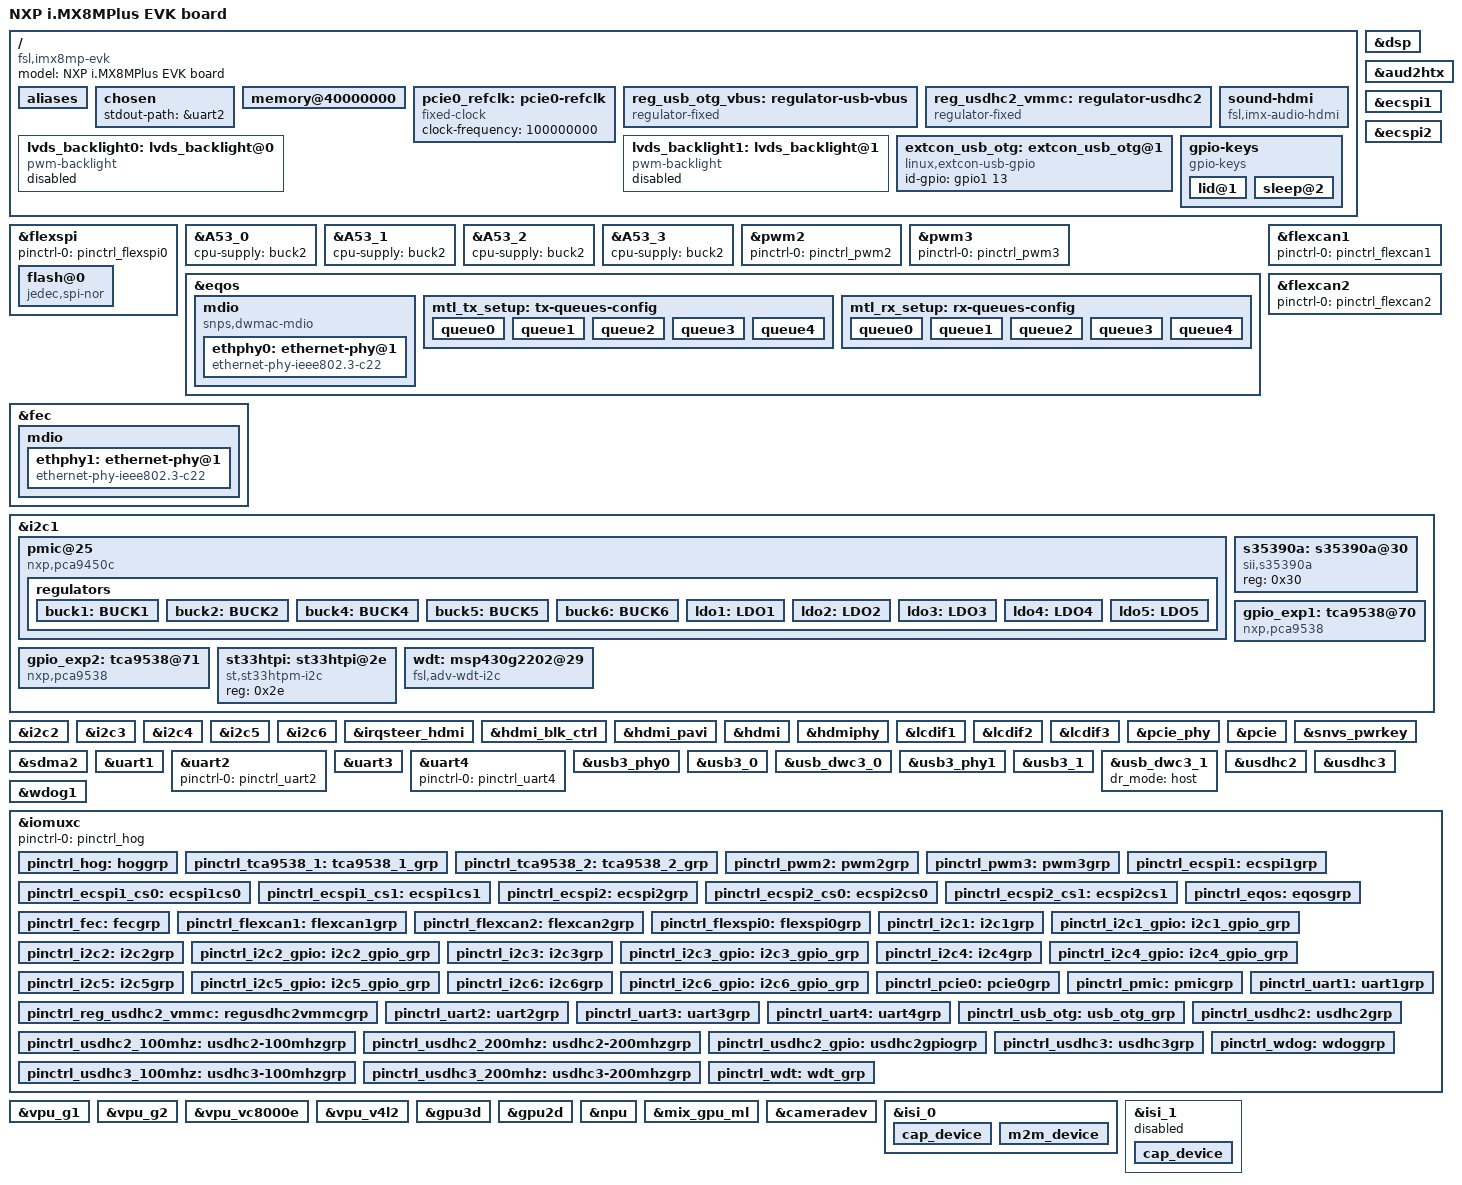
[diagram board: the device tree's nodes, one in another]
// SPDX-License-Identifier: (GPL-2.0+ OR MIT)
/*
 * Copyright 2019 NXP
 */

/dts-v1/;

#include <dt-bindings/phy/phy-imx8-pcie.h>
#include <dt-bindings/usb/pd.h>
#include "imx8mp.dtsi"
#include "imx8mp-nxp-display.dtsi"
#include "imx8mp-nxp-capture.dtsi"

/ {
	model = "NXP i.MX8MPlus EVK board";
	compatible = "fsl,imx8mp-evk", "fsl,imx8mp";

	aliases {
		rtc0 = &s35390a;
		rtc1 = &snvs_rtc;
	};

	aliases {
		watchdog0 = &wdog1;
		watchdog1 = &wdt;
	};

	chosen {
		stdout-path = &uart2;
	};

	memory@40000000 {
		device_type = "memory";
		reg = <0x0 0x40000000 0 0xc0000000>,
		      <0x1 0x00000000 0 0xc0000000>;
	};

	pcie0_refclk: pcie0-refclk {
		compatible = "fixed-clock";
		#clock-cells = <0>;
		clock-frequency = <100000000>;
	};

	reg_usb_otg_vbus: regulator-usb-vbus {
		compatible = "regulator-fixed";
		regulator-name = "usb_otg_vbus";
		regulator-min-microvolt = <5000000>;
		regulator-max-microvolt = <5000000>;
		gpio = <&gpio1 12 GPIO_ACTIVE_HIGH>;
		enable-active-high;
		regulator-always-on;
	};

	reg_usdhc2_vmmc: regulator-usdhc2 {
		compatible = "regulator-fixed";
		pinctrl-names = "default";
		pinctrl-0 = <&pinctrl_reg_usdhc2_vmmc>;
		regulator-name = "VSD_3V3";
		regulator-min-microvolt = <3300000>;
		regulator-max-microvolt = <3300000>;
		gpio = <&gpio2 19 GPIO_ACTIVE_HIGH>;
		enable-active-high;
	};

	sound-hdmi {
		compatible = "fsl,imx-audio-hdmi";
		model = "audio-hdmi";
		audio-cpu = <&aud2htx>;
		hdmi-out;
		constraint-rate = <44100>,
				<88200>,
				<176400>,
				<32000>,
				<48000>,
				<96000>,
				<192000>;
		status = "okay";
	};

	lvds_backlight0: lvds_backlight@0 {
		compatible = "pwm-backlight";
		pwms = <&pwm2 0 5000000 0>;
		status = "disabled";

		brightness-levels = < 0  1  2  3  4  5  6  7  8  9
				     10 11 12 13 14 15 16 17 18 19
				     20 21 22 23 24 25 26 27 28 29
				     30 31 32 33 34 35 36 37 38 39
				     40 41 42 43 44 45 46 47 48 49
				     50 51 52 53 54 55 56 57 58 59
				     60 61 62 63 64 65 66 67 68 69
				     70 71 72 73 74 75 76 77 78 79
				     80 81 82 83 84 85 86 87 88 89
				     90 91 92 93 94 95 96 97 98 99
				    100>;
		default-brightness-level = <80>;
	};

	lvds_backlight1: lvds_backlight@1 {
		compatible = "pwm-backlight";
		pwms = <&pwm3 0 5000000 0>;
		status = "disabled";

		brightness-levels = < 0  1  2  3  4  5  6  7  8  9
				     10 11 12 13 14 15 16 17 18 19
				     20 21 22 23 24 25 26 27 28 29
				     30 31 32 33 34 35 36 37 38 39
				     40 41 42 43 44 45 46 47 48 49
				     50 51 52 53 54 55 56 57 58 59
				     60 61 62 63 64 65 66 67 68 69
				     70 71 72 73 74 75 76 77 78 79
				     80 81 82 83 84 85 86 87 88 89
				     90 91 92 93 94 95 96 97 98 99
				    100>;
		default-brightness-level = <80>;
	};

	extcon_usb_otg: extcon_usb_otg@1 {
		compatible = "linux,extcon-usb-gpio";
		id-gpio = <&gpio1 13 GPIO_ACTIVE_HIGH>;
	};

	gpio-keys {
		compatible = "gpio-keys";
		#address-cells = <1>;
		#size-cells = <0>;
		pinctrl-names = "default";

		lid@1 {
			label = "LID KEY";
			gpios = <&gpio_exp1 6 GPIO_ACTIVE_HIGH>;
			linux,input-type = <EV_PWR>; //EV_KEY 1, EV_PWR 22
			linux,code = <KEY_SUSPEND>; //KEY_SUSPEND 205, KEY_SLEEP 142, KEY_POWER 116
			wakeup-source;
			debounce-interval = <100>;
		};

		sleep@2 {
			label = "SLEEP KEY";
			gpios = <&gpio_exp1 7 GPIO_ACTIVE_HIGH>;
			linux,input-type = <EV_PWR>; //EV_KEY 1, EV_PWR 22
			linux,code = <KEY_SLEEP>; //KEY_SUSPEND 205, KEY_SLEEP 142, KEY_POWER 116
			wakeup-source;
			debounce-interval = <100>;
		};
	};
};

&flexspi {
	pinctrl-names = "default";
	pinctrl-0 = <&pinctrl_flexspi0>;
	status = "okay";

	flash@0 {
		compatible = "jedec,spi-nor";
		reg = <0>;
		spi-max-frequency = <29000000>;
		spi-tx-bus-width = <4>;
		spi-rx-bus-width = <4>;
	};
};

&A53_0 {
	cpu-supply = <&buck2>;
};

&A53_1 {
	cpu-supply = <&buck2>;
};

&A53_2 {
	cpu-supply = <&buck2>;
};

&A53_3 {
	cpu-supply = <&buck2>;
};

&dsp {
	status = "okay";
};

&pwm2 {
	pinctrl-names = "default";
	pinctrl-0 = <&pinctrl_pwm2>;
	status = "okay";
};

&pwm3 {
	pinctrl-names = "default";
	pinctrl-0 = <&pinctrl_pwm3>;
	status = "okay";
};

&aud2htx {
	status = "okay";
};

&ecspi1 {
	#address-cells = <1>;
	#size-cells = <0>;
	fsl,spi-num-chipselects = <2>;
	pinctrl-names = "default";
	pinctrl-0 = <&pinctrl_ecspi1 &pinctrl_ecspi1_cs0 &pinctrl_ecspi1_cs1>;
	cs-gpios = <&gpio5 9 GPIO_ACTIVE_LOW>, <&gpio1 7 GPIO_ACTIVE_LOW>;
	status = "okay";
};

&ecspi2 {
	#address-cells = <1>;
	#size-cells = <0>;
	fsl,spi-num-chipselects = <2>;
	pinctrl-names = "default";
	pinctrl-0 = <&pinctrl_ecspi2 &pinctrl_ecspi2_cs0 &pinctrl_ecspi2_cs1>;
	cs-gpios = <&gpio5 13 GPIO_ACTIVE_LOW>, <&gpio1 8 GPIO_ACTIVE_LOW>;
	status = "okay";
};

&eqos {
	pinctrl-names = "default";
	pinctrl-0 = <&pinctrl_eqos>;
	phy-mode = "rgmii-id";
	phy-handle = <&ethphy0>;
	snps,force_thresh_dma_mode;
	snps,mtl-tx-config = <&mtl_tx_setup>;
	snps,mtl-rx-config = <&mtl_rx_setup>;
	status = "okay";

	mdio {
		compatible = "snps,dwmac-mdio";
		#address-cells = <1>;
		#size-cells = <0>;

		ethphy0: ethernet-phy@1 {
			compatible = "ethernet-phy-ieee802.3-c22";
			reg = <1>;
			eee-broken-1000t;
			reset-gpios = <&gpio4 22 GPIO_ACTIVE_LOW>;
			reset-assert-us = <10000>;
			reset-deassert-us = <80000>;
			realtek,clkout-disable;
		};
	};

	mtl_tx_setup: tx-queues-config {
		snps,tx-queues-to-use = <5>;
		snps,tx-sched-sp;

		queue0 {
			snps,dcb-algorithm;
			snps,priority = <0x1>;
		};

		queue1 {
			snps,dcb-algorithm;
			snps,priority = <0x2>;
		};

		queue2 {
			snps,dcb-algorithm;
			snps,priority = <0x4>;
		};

		queue3 {
			snps,dcb-algorithm;
			snps,priority = <0x8>;
		};

		queue4 {
			snps,dcb-algorithm;
			snps,priority = <0xf0>;
		};
	};

	mtl_rx_setup: rx-queues-config {
		snps,rx-queues-to-use = <5>;
		snps,rx-sched-sp;

		queue0 {
			snps,dcb-algorithm;
			snps,priority = <0x1>;
			snps,map-to-dma-channel = <0>;
		};

		queue1 {
			snps,dcb-algorithm;
			snps,priority = <0x2>;
			snps,map-to-dma-channel = <1>;
		};

		queue2 {
			snps,dcb-algorithm;
			snps,priority = <0x4>;
			snps,map-to-dma-channel = <2>;
		};

		queue3 {
			snps,dcb-algorithm;
			snps,priority = <0x8>;
			snps,map-to-dma-channel = <3>;
		};

		queue4 {
			snps,dcb-algorithm;
			snps,priority = <0xf0>;
			snps,map-to-dma-channel = <4>;
		};
	};
};

&fec {
	pinctrl-names = "default";
	pinctrl-0 = <&pinctrl_fec>;
	phy-mode = "rgmii-id";
	phy-handle = <&ethphy1>;
	fsl,magic-packet;
	status = "okay";

	mdio {
		#address-cells = <1>;
		#size-cells = <0>;

		ethphy1: ethernet-phy@1 {
			compatible = "ethernet-phy-ieee802.3-c22";
			reg = <1>;
			eee-broken-1000t;
			reset-gpios = <&gpio4 2 GPIO_ACTIVE_LOW>;
			reset-assert-us = <10000>;
			reset-deassert-us = <80000>;
			realtek,aldps-enable;
			realtek,clkout-disable;
		};
	};
};

&flexcan1 {
	pinctrl-names = "default";
	pinctrl-0 = <&pinctrl_flexcan1>;
	status = "okay";
};

&flexcan2 {
	pinctrl-names = "default";
	pinctrl-0 = <&pinctrl_flexcan2>;
	status = "okay";
};

&i2c1 {
	clock-frequency = <400000>;
	pinctrl-names = "default", "gpio";
	pinctrl-0 = <&pinctrl_i2c1>;
	pinctrl-1 = <&pinctrl_i2c1_gpio>;
	scl-gpios = <&gpio5 14 GPIO_ACTIVE_HIGH>;
	sda-gpios = <&gpio5 15 GPIO_ACTIVE_HIGH>;
	status = "okay";

	pmic@25 {
		compatible = "nxp,pca9450c";
		reg = <0x25>;
		pinctrl-names = "default";
		pinctrl-0 = <&pinctrl_pmic>;
		interrupt-parent = <&gpio1>;
		interrupts = <3 IRQ_TYPE_LEVEL_LOW>;
		nxp,i2c-lt-enable;

		regulators {
			buck1: BUCK1 {
				regulator-name = "BUCK1";
				regulator-min-microvolt = <600000>;
				regulator-max-microvolt = <2187500>;
				regulator-boot-on;
				regulator-always-on;
				regulator-ramp-delay = <3125>;
			};

			buck2: BUCK2 {
				regulator-name = "BUCK2";
				regulator-min-microvolt = <600000>;
				regulator-max-microvolt = <2187500>;
				regulator-boot-on;
				regulator-always-on;
				regulator-ramp-delay = <3125>;
				nxp,dvs-run-voltage = <950000>;
				nxp,dvs-standby-voltage = <850000>;
			};

			buck4: BUCK4{
				regulator-name = "BUCK4";
				regulator-min-microvolt = <600000>;
				regulator-max-microvolt = <3400000>;
				regulator-boot-on;
				regulator-always-on;
			};

			buck5: BUCK5{
				regulator-name = "BUCK5";
				regulator-min-microvolt = <600000>;
				regulator-max-microvolt = <3400000>;
				regulator-boot-on;
				regulator-always-on;
			};

			buck6: BUCK6 {
				regulator-name = "BUCK6";
				regulator-min-microvolt = <600000>;
				regulator-max-microvolt = <3400000>;
				regulator-boot-on;
				regulator-always-on;
			};

			ldo1: LDO1 {
				regulator-name = "LDO1";
				regulator-min-microvolt = <1600000>;
				regulator-max-microvolt = <3300000>;
				regulator-boot-on;
				regulator-always-on;
			};

			ldo2: LDO2 {
				regulator-name = "LDO2";
				regulator-min-microvolt = <800000>;
				regulator-max-microvolt = <1150000>;
				regulator-boot-on;
				regulator-always-on;
			};

			ldo3: LDO3 {
				regulator-name = "LDO3";
				regulator-min-microvolt = <800000>;
				regulator-max-microvolt = <3300000>;
				regulator-boot-on;
				regulator-always-on;
			};

			ldo4: LDO4 {
				regulator-name = "LDO4";
				regulator-min-microvolt = <800000>;
				regulator-max-microvolt = <3300000>;
				regulator-boot-on;
				regulator-always-on;
			};

			ldo5: LDO5 {
				regulator-name = "LDO5";
				regulator-min-microvolt = <1800000>;
				regulator-max-microvolt = <3300000>;
				regulator-boot-on;
				regulator-always-on;
			};
		};
	};

	s35390a: s35390a@30 {
		compatible = "sii,s35390a";
		reg = <0x30>;
		status = "okay";
	};

	gpio_exp1: tca9538@70 {
		compatible = "nxp,pca9538";
		reg = <0x70>;
		pinctrl-0 = <&pinctrl_tca9538_1>;
		interrupt-parent = <&gpio4>;
		interrupts = <0 IRQ_TYPE_EDGE_FALLING>;
		gpio-controller;
		#gpio-cells = <2>;
		interrupt-controller;
		#interrupt-cells = <2>;
	};

	gpio_exp2: tca9538@71 {
		compatible = "nxp,pca9538";
		reg = <0x71>;
		pinctrl-0 = <&pinctrl_tca9538_2>;
		interrupt-parent = <&gpio4>;
		interrupts = <1 IRQ_TYPE_EDGE_FALLING>;
		gpio-controller;
		#gpio-cells = <2>;
		interrupt-controller;
		#interrupt-cells = <2>;
	};

	st33htpi: st33htpi@2e {
		compatible = "st,st33htpm-i2c";
		reg = <0x2e>;
		pinctrl-names = "default";
	};

	wdt: msp430g2202@29 {
		compatible = "fsl,adv-wdt-i2c";
		reg = <0x29>;
		pinctrl-names = "default";
		pinctrl-0 = <&pinctrl_wdt>;
		wdt-en-gpio = <&gpio3 19 GPIO_ACTIVE_HIGH>;
		wdt-ping-gpio = <&gpio4 20 GPIO_ACTIVE_HIGH>;
		status = "okay";
	};
};

&i2c2 {
	clock-frequency = <400000>;
	pinctrl-names = "default", "gpio";
	pinctrl-0 = <&pinctrl_i2c2>;
	pinctrl-1 = <&pinctrl_i2c2_gpio>;
	scl-gpios = <&gpio5 16 GPIO_ACTIVE_HIGH>;
	sda-gpios = <&gpio5 17 GPIO_ACTIVE_HIGH>;
	status = "okay";
};

&i2c3 {
	clock-frequency = <400000>;
	pinctrl-names = "default", "gpio";
	pinctrl-0 = <&pinctrl_i2c3>;
	pinctrl-1 = <&pinctrl_i2c3_gpio>;
	scl-gpios = <&gpio5 18 GPIO_ACTIVE_HIGH>;
	sda-gpios = <&gpio5 19 GPIO_ACTIVE_HIGH>;
	status = "okay";
};

&i2c4 {
	clock-frequency = <100000>;
	pinctrl-names = "default", "gpio";
	pinctrl-0 = <&pinctrl_i2c4>;
	pinctrl-1 = <&pinctrl_i2c4_gpio>;
	scl-gpios = <&gpio2 4 GPIO_ACTIVE_HIGH>;
	sda-gpios = <&gpio2 5 GPIO_ACTIVE_HIGH>;
	status = "okay";
};

&i2c5 {
	clock-frequency = <100000>;
	pinctrl-names = "default", "gpio";
	pinctrl-0 = <&pinctrl_i2c5>;
	pinctrl-1 = <&pinctrl_i2c5_gpio>;
	scl-gpios = <&gpio2 0 GPIO_ACTIVE_HIGH>;
	sda-gpios = <&gpio2 1 GPIO_ACTIVE_HIGH>;
	status = "okay";
};

&i2c6 {
	clock-frequency = <100000>;
	pinctrl-names = "default", "gpio";
	pinctrl-0 = <&pinctrl_i2c6>;
	pinctrl-1 = <&pinctrl_i2c6_gpio>;
	scl-gpios = <&gpio3 28 GPIO_ACTIVE_HIGH>;
	sda-gpios = <&gpio3 20 GPIO_ACTIVE_HIGH>;
	status = "okay";
};

&irqsteer_hdmi {
	status = "okay";
};

&hdmi_blk_ctrl {
	status = "okay";
};

&hdmi_pavi {
	status = "okay";
};

&hdmi {
	status = "okay";
};

&hdmiphy {
	status = "okay";
};

&lcdif1 {
	status = "okay";
};

&lcdif2 {
	status = "okay";
};

&lcdif3 {
	status = "okay";

	thres-low  = <1 2>;             /* (FIFO * 1 / 2) */
	thres-high = <3 4>;             /* (FIFO * 3 / 4) */
};

&pcie_phy {
	fsl,refclk-pad-mode = <IMX8_PCIE_REFCLK_PAD_INPUT>;
	clocks = <&pcie0_refclk>;
	clock-names = "ref";
	status = "okay";
};

&pcie {
	pinctrl-names = "default";
	pinctrl-0 = <&pinctrl_pcie0>;
	reset-gpio = <&gpio1 9 GPIO_ACTIVE_LOW>;      /* M2_RESET# */
	clocks = <&clk IMX8MP_CLK_HSIO_ROOT>,
		 <&clk IMX8MP_CLK_PCIE_ROOT>,
		 <&clk IMX8MP_CLK_HSIO_AXI>;
	clock-names = "pcie", "pcie_aux", "pcie_bus";
	assigned-clocks = <&clk IMX8MP_CLK_PCIE_AUX>;
	assigned-clock-rates = <10000000>;
	assigned-clock-parents = <&clk IMX8MP_SYS_PLL2_50M>;
	status = "okay";
};

&snvs_pwrkey {
	status = "okay";
};

&sdma2 {
	status = "okay";
};

&uart1 { /* BT */
	pinctrl-names = "default";
	pinctrl-0 = <&pinctrl_uart1>;
	assigned-clocks = <&clk IMX8MP_CLK_UART1>;
	assigned-clock-parents = <&clk IMX8MP_SYS_PLL1_80M>;
	uart-has-rtscts;
	status = "okay";
};

&uart2 {
	/* console */
	pinctrl-names = "default";
	pinctrl-0 = <&pinctrl_uart2>;
	status = "okay";
};

&uart3 {
	pinctrl-names = "default";
	pinctrl-0 = <&pinctrl_uart3>;
	assigned-clocks = <&clk IMX8MP_CLK_UART3>;
	assigned-clock-parents = <&clk IMX8MP_SYS_PLL1_80M>;
	fsl,uart-has-rtscts;
	linux,rs485-enabled-at-boot-time;
	rs485-rx-during-tx;
	rs485-rts-active-low;
	status = "okay";
};

&uart4 {
	pinctrl-names = "default";
	pinctrl-0 = <&pinctrl_uart4>;
	status = "okay";
};

&usb3_phy0 {
	fsl,phy-tx-vref-tune = <0xe>;
	fsl,phy-tx-preemp-amp-tune = <3>;
	fsl,phy-tx-vboost-level = <5>;
	fsl,phy-comp-dis-tune = <7>;
	fsl,pcs-tx-deemph-3p5db = <0x21>;
	fsl,phy-pcs-tx-swing-full = <0x7f>;
	status = "okay";
};

&usb3_0 {
	status = "okay";
};

&usb_dwc3_0 {
	pinctrl-names = "default";
	pinctrl-0 = <&pinctrl_usb_otg>;
	dr_mode = "otg";
	extcon = <&extcon_usb_otg>;
	vbus-supply = <&reg_usb_otg_vbus>;
	status = "okay";
};

&usb3_phy1 {
	fsl,phy-tx-preemp-amp-tune = <3>;
	fsl,phy-tx-vref-tune = <0xb>;
	status = "okay";
};

&usb3_1 {
	status = "okay";
};

&usb_dwc3_1 {
	dr_mode = "host";
	status = "okay";
};

&usdhc2 {
	assigned-clocks = <&clk IMX8MP_CLK_USDHC2>;
	assigned-clock-rates = <400000000>;
	pinctrl-names = "default", "state_100mhz", "state_200mhz";
	pinctrl-0 = <&pinctrl_usdhc2>, <&pinctrl_usdhc2_gpio>;
	pinctrl-1 = <&pinctrl_usdhc2_100mhz>, <&pinctrl_usdhc2_gpio>;
	pinctrl-2 = <&pinctrl_usdhc2_200mhz>, <&pinctrl_usdhc2_gpio>;
	wp-gpios = <&gpio2 20 GPIO_ACTIVE_HIGH>;
	cd-gpios = <&gpio2 12 GPIO_ACTIVE_LOW>;
	vmmc-supply = <&reg_usdhc2_vmmc>;
	bus-width = <4>;
	status = "okay";
};

&usdhc3 {
	assigned-clocks = <&clk IMX8MP_CLK_USDHC3>;
	assigned-clock-rates = <400000000>;
	pinctrl-names = "default", "state_100mhz", "state_200mhz";
	pinctrl-0 = <&pinctrl_usdhc3>;
	pinctrl-1 = <&pinctrl_usdhc3_100mhz>;
	pinctrl-2 = <&pinctrl_usdhc3_200mhz>;
	bus-width = <8>;
	cqe-disabled;
	non-removable;
	status = "okay";
};

&wdog1 {
	pinctrl-names = "default";
	pinctrl-0 = <&pinctrl_wdog>;
	fsl,ext-reset-output;
	status = "okay";
};

&iomuxc {
	pinctrl-names = "default";
	pinctrl-0 = <&pinctrl_hog>;

	pinctrl_hog: hoggrp {
		fsl,pins = <
			MX8MP_IOMUXC_HDMI_DDC_SCL__HDMIMIX_HDMI_SCL	0x400001c2
			MX8MP_IOMUXC_HDMI_DDC_SDA__HDMIMIX_HDMI_SDA	0x400001c2
			MX8MP_IOMUXC_HDMI_HPD__HDMIMIX_HDMI_HPD		0x40000010
			MX8MP_IOMUXC_SAI2_MCLK__GPIO4_IO27		0x10		/* GPIO4 */
			MX8MP_IOMUXC_SPDIF_EXT_CLK__GPIO5_IO05	0x10		/* GPIO5 */
			MX8MP_IOMUXC_UART3_RXD__GPIO5_IO26		0x10		/* GPIO6 */
			MX8MP_IOMUXC_UART3_TXD__GPIO5_IO27		0x10		/* GPIO7 */
		>;
	};

	pinctrl_tca9538_1: tca9538_1_grp {
		fsl,pins = <
			MX8MP_IOMUXC_SAI1_RXFS__GPIO4_IO00	0x1c4	/* I2C_EXP_INT0# */
		>;
	};

	pinctrl_tca9538_2: tca9538_2_grp {
		fsl,pins = <
			MX8MP_IOMUXC_SAI1_RXC__GPIO4_IO01	0x1c4	/* I2C_EXP_INT1# */
		>;
	};

	pinctrl_pwm2: pwm2grp {
		fsl,pins = <
			MX8MP_IOMUXC_SAI5_RXD0__PWM2_OUT	0x116
		>;
	};

	pinctrl_pwm3: pwm3grp {
		fsl,pins = <
			MX8MP_IOMUXC_GPIO1_IO10__PWM3_OUT		0x116
		>;
	};

	pinctrl_ecspi1: ecspi1grp {
		fsl,pins = <
			MX8MP_IOMUXC_ECSPI1_SCLK__ECSPI1_SCLK           0x82
			MX8MP_IOMUXC_ECSPI1_MOSI__ECSPI1_MOSI           0x82
			MX8MP_IOMUXC_ECSPI1_MISO__ECSPI1_MISO           0x82
		>;
	};

	pinctrl_ecspi1_cs0: ecspi1cs0 {
		fsl,pins = <
			MX8MP_IOMUXC_ECSPI1_SS0__GPIO5_IO09             0x10
		>;
	};

	pinctrl_ecspi1_cs1: ecspi1cs1 {
		fsl,pins = <
			MX8MP_IOMUXC_GPIO1_IO07__GPIO1_IO07             0x10
		>;
	};

	pinctrl_ecspi2: ecspi2grp {
		fsl,pins = <
			MX8MP_IOMUXC_ECSPI2_SCLK__ECSPI2_SCLK           0x82
			MX8MP_IOMUXC_ECSPI2_MOSI__ECSPI2_MOSI           0x82
			MX8MP_IOMUXC_ECSPI2_MISO__ECSPI2_MISO           0x82
		>;
	};

	pinctrl_ecspi2_cs0: ecspi2cs0 {
		fsl,pins = <
			MX8MP_IOMUXC_ECSPI2_SS0__GPIO5_IO13             0x10
		>;
	};

	pinctrl_ecspi2_cs1: ecspi2cs1 {
		fsl,pins = <
			MX8MP_IOMUXC_GPIO1_IO08__GPIO1_IO08             0x10
		>;
	};

	pinctrl_eqos: eqosgrp {
		fsl,pins = <
			MX8MP_IOMUXC_ENET_MDC__ENET_QOS_MDC				0x2
			MX8MP_IOMUXC_ENET_MDIO__ENET_QOS_MDIO				0x2
			MX8MP_IOMUXC_ENET_RD0__ENET_QOS_RGMII_RD0			0x90
			MX8MP_IOMUXC_ENET_RD1__ENET_QOS_RGMII_RD1			0x90
			MX8MP_IOMUXC_ENET_RD2__ENET_QOS_RGMII_RD2			0x90
			MX8MP_IOMUXC_ENET_RD3__ENET_QOS_RGMII_RD3			0x90
			MX8MP_IOMUXC_ENET_RXC__CCM_ENET_QOS_CLOCK_GENERATE_RX_CLK	0x90
			MX8MP_IOMUXC_ENET_RX_CTL__ENET_QOS_RGMII_RX_CTL			0x90
			MX8MP_IOMUXC_ENET_TD0__ENET_QOS_RGMII_TD0			0x16
			MX8MP_IOMUXC_ENET_TD1__ENET_QOS_RGMII_TD1			0x16
			MX8MP_IOMUXC_ENET_TD2__ENET_QOS_RGMII_TD2			0x16
			MX8MP_IOMUXC_ENET_TD3__ENET_QOS_RGMII_TD3			0x16
			MX8MP_IOMUXC_ENET_TX_CTL__ENET_QOS_RGMII_TX_CTL			0x16
			MX8MP_IOMUXC_ENET_TXC__CCM_ENET_QOS_CLOCK_GENERATE_TX_CLK	0x16
			MX8MP_IOMUXC_SAI2_RXC__GPIO4_IO22				0x10
			MX8MP_IOMUXC_SAI2_RXFS__GPIO4_IO21				0x1c4	/* ENET_INT# */
		>;
	};

	pinctrl_fec: fecgrp {
		fsl,pins = <
			MX8MP_IOMUXC_SAI1_RXD2__ENET1_MDC		0x2
			MX8MP_IOMUXC_SAI1_RXD3__ENET1_MDIO		0x2
			MX8MP_IOMUXC_SAI1_RXD4__ENET1_RGMII_RD0		0x90
			MX8MP_IOMUXC_SAI1_RXD5__ENET1_RGMII_RD1		0x90
			MX8MP_IOMUXC_SAI1_RXD6__ENET1_RGMII_RD2		0x90
			MX8MP_IOMUXC_SAI1_RXD7__ENET1_RGMII_RD3		0x90
			MX8MP_IOMUXC_SAI1_TXC__ENET1_RGMII_RXC		0x90
			MX8MP_IOMUXC_SAI1_TXFS__ENET1_RGMII_RX_CTL	0x90
			MX8MP_IOMUXC_SAI1_TXD0__ENET1_RGMII_TD0		0x16
			MX8MP_IOMUXC_SAI1_TXD1__ENET1_RGMII_TD1		0x16
			MX8MP_IOMUXC_SAI1_TXD2__ENET1_RGMII_TD2		0x16
			MX8MP_IOMUXC_SAI1_TXD3__ENET1_RGMII_TD3		0x16
			MX8MP_IOMUXC_SAI1_TXD4__ENET1_RGMII_TX_CTL	0x16
			MX8MP_IOMUXC_SAI1_TXD5__ENET1_RGMII_TXC		0x16
			MX8MP_IOMUXC_SAI1_RXD0__GPIO4_IO02		0x10
			MX8MP_IOMUXC_SAI1_RXD1__GPIO4_IO03		0x1c4	/* ENET1_INT# */
		>;
	};

	pinctrl_flexcan1: flexcan1grp {
		fsl,pins = <
			MX8MP_IOMUXC_SPDIF_RX__CAN1_RX          0x154
			MX8MP_IOMUXC_SPDIF_TX__CAN1_TX          0x154
		>;
	};

	pinctrl_flexcan2: flexcan2grp {
		fsl,pins = <
			MX8MP_IOMUXC_SAI5_MCLK__CAN2_RX         0x154
			MX8MP_IOMUXC_SAI5_RXD3__CAN2_TX         0x154
		>;
	};

	pinctrl_flexspi0: flexspi0grp {
		fsl,pins = <
			MX8MP_IOMUXC_NAND_ALE__FLEXSPI_A_SCLK           0x1c2
			MX8MP_IOMUXC_NAND_CE0_B__FLEXSPI_A_SS0_B        0x82
			MX8MP_IOMUXC_NAND_DATA00__FLEXSPI_A_DATA00      0x82
			MX8MP_IOMUXC_NAND_DATA01__FLEXSPI_A_DATA01      0x82
			MX8MP_IOMUXC_NAND_DATA02__FLEXSPI_A_DATA02      0x82
			MX8MP_IOMUXC_NAND_DATA03__FLEXSPI_A_DATA03      0x82
		>;
	};

	pinctrl_i2c1: i2c1grp {
		fsl,pins = <
			MX8MP_IOMUXC_I2C1_SCL__I2C1_SCL		0x400001c2
			MX8MP_IOMUXC_I2C1_SDA__I2C1_SDA		0x400001c2
		>;
	};

	pinctrl_i2c1_gpio: i2c1_gpio_grp  {
		fsl,pins = <
			MX8MP_IOMUXC_I2C1_SCL__GPIO5_IO14		0x10
			MX8MP_IOMUXC_I2C1_SDA__GPIO5_IO15		0x10
		>;
	};

	pinctrl_i2c2: i2c2grp {
		fsl,pins = <
			MX8MP_IOMUXC_I2C2_SCL__I2C2_SCL		0x400001c2
			MX8MP_IOMUXC_I2C2_SDA__I2C2_SDA		0x400001c2
		>;
	};

	pinctrl_i2c2_gpio: i2c2_gpio_grp  {
		fsl,pins = <
			MX8MP_IOMUXC_I2C2_SCL__GPIO5_IO16		0x10
			MX8MP_IOMUXC_I2C2_SDA__GPIO5_IO17		0x10
		>;
	};

	pinctrl_i2c3: i2c3grp {
		fsl,pins = <
			MX8MP_IOMUXC_I2C3_SCL__I2C3_SCL		0x400001c2
			MX8MP_IOMUXC_I2C3_SDA__I2C3_SDA		0x400001c2
		>;
	};

	pinctrl_i2c3_gpio: i2c3_gpio_grp  {
		fsl,pins = <
			MX8MP_IOMUXC_I2C3_SCL__GPIO5_IO18		0x10
			MX8MP_IOMUXC_I2C3_SDA__GPIO5_IO19		0x10
		>;
	};

	pinctrl_i2c4: i2c4grp {
		fsl,pins = <
			MX8MP_IOMUXC_SD1_DATA2__I2C4_SCL		0x400001c2
			MX8MP_IOMUXC_SD1_DATA3__I2C4_SDA		0x400001c2
		>;
	};

	pinctrl_i2c4_gpio: i2c4_gpio_grp  {
		fsl,pins = <
			MX8MP_IOMUXC_SD1_DATA2__GPIO2_IO04		0x10
			MX8MP_IOMUXC_SD1_DATA3__GPIO2_IO05		0x10
		>;
	};

	pinctrl_i2c5: i2c5grp {
		fsl,pins = <
			MX8MP_IOMUXC_SD1_CLK__I2C5_SCL			0x400001c2
			MX8MP_IOMUXC_SD1_CMD__I2C5_SDA			0x400001c2
		>;
	};

	pinctrl_i2c5_gpio: i2c5_gpio_grp  {
		fsl,pins = <
			MX8MP_IOMUXC_SD1_CLK__GPIO2_IO00		0x10
			MX8MP_IOMUXC_SD1_CMD__GPIO2_IO01		0x10
		>;
	};

	pinctrl_i2c6: i2c6grp {
		fsl,pins = <
			MX8MP_IOMUXC_HDMI_CEC__I2C6_SCL			0x400001c2
			MX8MP_IOMUXC_SAI5_RXC__I2C6_SDA			0x400001c2
		>;
	};

	pinctrl_i2c6_gpio: i2c6_gpio_grp  {
		fsl,pins = <
			MX8MP_IOMUXC_HDMI_CEC__GPIO3_IO28		0x10
			MX8MP_IOMUXC_SAI5_RXC__GPIO3_IO20		0x10
		>;
	};

	pinctrl_pcie0: pcie0grp {
		fsl,pins = <
			MX8MP_IOMUXC_I2C4_SCL__PCIE_CLKREQ_B	0x60 /* open drain, pull up */
			MX8MP_IOMUXC_I2C4_SDA__GPIO5_IO21		0x1c4
			MX8MP_IOMUXC_GPIO1_IO09__GPIO1_IO09		0x40
		>;
	};

	pinctrl_pmic: pmicgrp {
		fsl,pins = <
			MX8MP_IOMUXC_GPIO1_IO03__GPIO1_IO03	0x000001c0
		>;
	};

	pinctrl_reg_usdhc2_vmmc: regusdhc2vmmcgrp {
		fsl,pins = <
			MX8MP_IOMUXC_SD2_RESET_B__GPIO2_IO19	0x40
		>;
	};

	pinctrl_uart1: uart1grp {
		fsl,pins = <
			MX8MP_IOMUXC_UART1_RXD__UART1_DCE_RX	0x140
			MX8MP_IOMUXC_UART1_TXD__UART1_DCE_TX	0x140
			MX8MP_IOMUXC_SD1_DATA0__UART1_DCE_RTS	0x140
			MX8MP_IOMUXC_SD1_DATA1__UART1_DCE_CTS	0x140
		>;
	};

	pinctrl_uart2: uart2grp {
		fsl,pins = <
			MX8MP_IOMUXC_UART2_RXD__UART2_DCE_RX	0x140
			MX8MP_IOMUXC_UART2_TXD__UART2_DCE_TX	0x140
		>;
	};

	pinctrl_uart3: uart3grp {
		fsl,pins = <
			MX8MP_IOMUXC_SD1_DATA7__UART3_DCE_RX		0x140
			MX8MP_IOMUXC_SD1_DATA6__UART3_DCE_TX		0x140
			MX8MP_IOMUXC_SD1_RESET_B__UART3_DCE_RTS		0x140
			MX8MP_IOMUXC_SD1_STROBE__UART3_DCE_CTS		0x140
		>;
	};

	pinctrl_uart4: uart4grp {
		fsl,pins = <
			MX8MP_IOMUXC_UART4_RXD__UART4_DCE_RX	0x140
			MX8MP_IOMUXC_UART4_TXD__UART4_DCE_TX	0x140
		>;
	};

	pinctrl_usb_otg: usb_otg_grp {
		fsl,pins = <
			MX8MP_IOMUXC_GPIO1_IO13__GPIO1_IO13     0x10
			MX8MP_IOMUXC_GPIO1_IO12__GPIO1_IO12     0x10
		>;
	};

	pinctrl_usdhc2: usdhc2grp {
		fsl,pins = <
			MX8MP_IOMUXC_SD2_CLK__USDHC2_CLK	0x190
			MX8MP_IOMUXC_SD2_CMD__USDHC2_CMD	0x1d0
			MX8MP_IOMUXC_SD2_DATA0__USDHC2_DATA0	0x1d0
			MX8MP_IOMUXC_SD2_DATA1__USDHC2_DATA1	0x1d0
			MX8MP_IOMUXC_SD2_DATA2__USDHC2_DATA2	0x1d0
			MX8MP_IOMUXC_SD2_DATA3__USDHC2_DATA3	0x1d0
			MX8MP_IOMUXC_GPIO1_IO04__USDHC2_VSELECT	0xc0
		>;
	};

	pinctrl_usdhc2_100mhz: usdhc2-100mhzgrp {
		fsl,pins = <
			MX8MP_IOMUXC_SD2_CLK__USDHC2_CLK	0x194
			MX8MP_IOMUXC_SD2_CMD__USDHC2_CMD	0x1d4
			MX8MP_IOMUXC_SD2_DATA0__USDHC2_DATA0	0x1d4
			MX8MP_IOMUXC_SD2_DATA1__USDHC2_DATA1	0x1d4
			MX8MP_IOMUXC_SD2_DATA2__USDHC2_DATA2	0x1d4
			MX8MP_IOMUXC_SD2_DATA3__USDHC2_DATA3	0x1d4
			MX8MP_IOMUXC_GPIO1_IO04__USDHC2_VSELECT 0xc0
		>;
	};

	pinctrl_usdhc2_200mhz: usdhc2-200mhzgrp {
		fsl,pins = <
			MX8MP_IOMUXC_SD2_CLK__USDHC2_CLK	0x196
			MX8MP_IOMUXC_SD2_CMD__USDHC2_CMD	0x1d6
			MX8MP_IOMUXC_SD2_DATA0__USDHC2_DATA0	0x1d6
			MX8MP_IOMUXC_SD2_DATA1__USDHC2_DATA1	0x1d6
			MX8MP_IOMUXC_SD2_DATA2__USDHC2_DATA2	0x1d6
			MX8MP_IOMUXC_SD2_DATA3__USDHC2_DATA3	0x1d6
			MX8MP_IOMUXC_GPIO1_IO04__USDHC2_VSELECT 0xc0
		>;
	};

	pinctrl_usdhc2_gpio: usdhc2gpiogrp {
		fsl,pins = <
			MX8MP_IOMUXC_SD2_CD_B__GPIO2_IO12	0x1c4
		>;
	};

	pinctrl_usdhc3: usdhc3grp {
		fsl,pins = <
			MX8MP_IOMUXC_NAND_WE_B__USDHC3_CLK	0x190
			MX8MP_IOMUXC_NAND_WP_B__USDHC3_CMD	0x1d0
			MX8MP_IOMUXC_NAND_DATA04__USDHC3_DATA0	0x1d0
			MX8MP_IOMUXC_NAND_DATA05__USDHC3_DATA1	0x1d0
			MX8MP_IOMUXC_NAND_DATA06__USDHC3_DATA2	0x1d0
			MX8MP_IOMUXC_NAND_DATA07__USDHC3_DATA3	0x1d0
			MX8MP_IOMUXC_NAND_RE_B__USDHC3_DATA4	0x1d0
			MX8MP_IOMUXC_NAND_CE2_B__USDHC3_DATA5	0x1d0
			MX8MP_IOMUXC_NAND_CE3_B__USDHC3_DATA6	0x1d0
			MX8MP_IOMUXC_NAND_CLE__USDHC3_DATA7	0x1d0
			MX8MP_IOMUXC_NAND_CE1_B__USDHC3_STROBE	0x190
		>;
	};

	pinctrl_usdhc3_100mhz: usdhc3-100mhzgrp {
		fsl,pins = <
			MX8MP_IOMUXC_NAND_WE_B__USDHC3_CLK	0x194
			MX8MP_IOMUXC_NAND_WP_B__USDHC3_CMD	0x1d4
			MX8MP_IOMUXC_NAND_DATA04__USDHC3_DATA0	0x1d4
			MX8MP_IOMUXC_NAND_DATA05__USDHC3_DATA1	0x1d4
			MX8MP_IOMUXC_NAND_DATA06__USDHC3_DATA2	0x1d4
			MX8MP_IOMUXC_NAND_DATA07__USDHC3_DATA3	0x1d4
			MX8MP_IOMUXC_NAND_RE_B__USDHC3_DATA4	0x1d4
			MX8MP_IOMUXC_NAND_CE2_B__USDHC3_DATA5	0x1d4
			MX8MP_IOMUXC_NAND_CE3_B__USDHC3_DATA6	0x1d4
			MX8MP_IOMUXC_NAND_CLE__USDHC3_DATA7	0x1d4
			MX8MP_IOMUXC_NAND_CE1_B__USDHC3_STROBE	0x194
		>;
	};

	pinctrl_usdhc3_200mhz: usdhc3-200mhzgrp {
		fsl,pins = <
			MX8MP_IOMUXC_NAND_WE_B__USDHC3_CLK	0x196
			MX8MP_IOMUXC_NAND_WP_B__USDHC3_CMD	0x1d6
			MX8MP_IOMUXC_NAND_DATA04__USDHC3_DATA0	0x1d6
			MX8MP_IOMUXC_NAND_DATA05__USDHC3_DATA1	0x1d6
			MX8MP_IOMUXC_NAND_DATA06__USDHC3_DATA2	0x1d6
			MX8MP_IOMUXC_NAND_DATA07__USDHC3_DATA3	0x1d6
			MX8MP_IOMUXC_NAND_RE_B__USDHC3_DATA4	0x1d6
			MX8MP_IOMUXC_NAND_CE2_B__USDHC3_DATA5	0x1d6
			MX8MP_IOMUXC_NAND_CE3_B__USDHC3_DATA6	0x1d6
			MX8MP_IOMUXC_NAND_CLE__USDHC3_DATA7	0x1d6
			MX8MP_IOMUXC_NAND_CE1_B__USDHC3_STROBE	0x196
		>;
	};

	pinctrl_wdog: wdoggrp {
		fsl,pins = <
			MX8MP_IOMUXC_GPIO1_IO02__WDOG1_WDOG_B	0x166
		>;
	};

	pinctrl_wdt: wdt_grp {
		fsl,pins = <
			MX8MP_IOMUXC_SAI5_RXFS__GPIO3_IO19      0x10    /* WDT_EN_1V8 */
			MX8MP_IOMUXC_SAI1_MCLK__GPIO4_IO20      0x10    /* WDT_TRIG_1V8 */
		>;
	};
};

&vpu_g1 {
	status = "okay";
};

&vpu_g2 {
	status = "okay";
};

&vpu_vc8000e {
	status = "okay";
};

&vpu_v4l2 {
	status = "okay";
};

&gpu3d {
	status = "okay";
};

&gpu2d {
	status = "okay";
};

&npu {
	status = "okay";
};

&mix_gpu_ml {
	status = "okay";
};

&cameradev {
	status = "okay";
};

&isi_0 {
	status = "okay";

	cap_device {
		status = "okay";
	};

	m2m_device {
		status = "okay";
	};
};

&isi_1 {
	status = "disabled";

	cap_device {
		status = "okay";
	};
};
